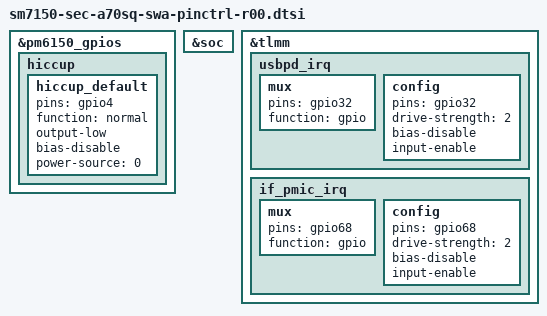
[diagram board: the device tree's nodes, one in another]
/* Copyright (c) 2019, The Linux Foundation. All rights reserved.
 *
 * This program is free software; you can redistribute it and/or modify
 * it under the terms of the GNU General Public License version 2 and
 * only version 2 as published by the Free Software Foundation.
 *
 * This program is distributed in the hope that it will be useful,
 * but WITHOUT ANY WARRANTY; without even the implied warranty of
 * MERCHANTABILITY or FITNESS FOR A PARTICULAR PURPOSE.  See the
 * GNU General Public License for more details.
 */

#include "sm7150-sec-a70sq-pinctrl-common.dtsi"

&pm6150_gpios {
	hiccup {
		hiccup_default: hiccup_default {
			pins = "gpio4";
			function = "normal";
			output-low;
			bias-disable;
			power-source = <0>;
		};
	};
};

&soc {
	
};

&tlmm {
	usbpd_irq: usbpd_irq {
		mux {
			pins = "gpio32";
	 		function = "gpio";
	 	};
		config {
	 		pins = "gpio32";
			drive-strength = <2>;
			bias-disable;
			input-enable;
	 	};
	};
	
	if_pmic_irq: if_pmic_irq {
		mux {
			pins = "gpio68";
			function = "gpio";
		};
		config {
			pins = "gpio68";
			drive-strength = <2>;   /* 16 mA */
			bias-disable;
			input-enable;
		};
	};
		
	
};
